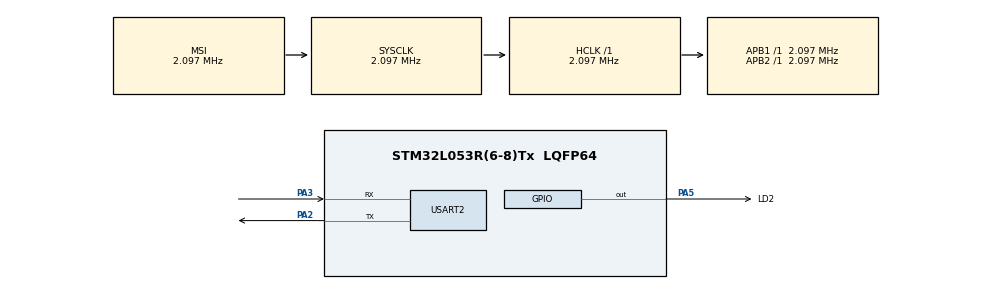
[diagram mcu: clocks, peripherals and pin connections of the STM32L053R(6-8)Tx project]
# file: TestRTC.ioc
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Mcu.Family=STM32L0
Mcu.Name=STM32L053R(6-8)Tx
Mcu.Package=LQFP64
NVIC.USART2_IRQn=true\:0\:0\:false\:false\:true\:true\:true
PA2.Mode=Asynchronous
PA2.Signal=USART2_TX
PA3.Mode=Asynchronous
PA3.Signal=USART2_RX
PA5.GPIO_Label=LD2
PA5.Signal=GPIO_Output
ProjectManager.HeapSize=0x200
ProjectManager.StackSize=0x400
ProjectManager.TargetToolchain=STM32CubeIDE
RCC.AHBFreq_Value=2097000
RCC.APB1Freq_Value=2097000
RCC.APB1TimFreq_Value=2097000
RCC.APB2Freq_Value=2097000
RCC.APB2TimFreq_Value=2097000
RCC.HSE_VALUE=8000000
RCC.HSI16_VALUE=16000000
RCC.HSI48_VALUE=48000000
RCC.HSI_VALUE=16000000
RCC.LSE_VALUE=32768
RCC.MSI_VALUE=2097000
RCC.SYSCLKFreq_VALUE=2097000
RCC.VCOOutputFreq_Value=48000000
RTC.Alarm-Alarm\ A=RTC_ALARM_A
RTC.Alarm_B-Alarm\ B=RTC_ALARM_B
RTC.Format=RTC_FORMAT_BIN
USART2.VirtualMode-Asynchronous=VM_ASYNC
VP_RTC_VS_RTC_Activate.Mode=RTC_Enabled
VP_RTC_VS_RTC_Alarm_A_Intern.Mode=Alarm A
VP_RTC_VS_RTC_Alarm_B_Intern.Mode=Alarm B
VP_RTC_VS_RTC_Calendar.Mode=RTC_Calendar
VP_RTC_VS_RTC_WakeUp_intern.Mode=WakeUp
board=custom

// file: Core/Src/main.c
/* USER CODE BEGIN Header */
/**
  ******************************************************************************
  * @file           : main.c
  * @brief          : Main program body
  ******************************************************************************
  * @attention
  *
  * <h2><center>&copy; Copyright (c) 2020 STMicroelectronics.
  * All rights reserved.</center></h2>
  *
  * This software component is licensed by ST under BSD 3-Clause license,
  * the "License"; You may not use this file except in compliance with the
  * License. You may obtain a copy of the License at:
  *                        opensource.org/licenses/BSD-3-Clause
  *
  ******************************************************************************
  */
/* USER CODE END Header */

#include "main.h"

/* USER CODE BEGIN Includes */
#include "gestionertc.h"
/* USER CODE END Includes */

RTC_HandleTypeDef hrtc;

UART_HandleTypeDef huart2;

/* USER CODE BEGIN PV */

uint32_t yesterday = 0;
uint32_t now = 0;
uint32_t errors = 0;

/* USER CODE END PV */

void SystemClock_Config(void);
static void MX_GPIO_Init(void);
static void MX_RTC_Init(void);
static void MX_USART2_UART_Init(void);
/* USER CODE BEGIN PFP */
static uint8_t doTest(uint32_t pattern, uint32_t seconds);
/* USER CODE END PFP */

int main(void)
{

  /* MCU Configuration--------------------------------------------------------*/

  /* Reset of all peripherals, Initializes the Flash interface and the Systick. */
  HAL_Init();

  /* Configure the system clock */
  SystemClock_Config();

  /* Initialize all configured peripherals */
  MX_GPIO_Init();
  MX_RTC_Init();
  MX_USART2_UART_Init();
  /* USER CODE BEGIN 2 */

  //SetOra(1580176798);

  uint32_t testPattern[24]={
		  1580176798,
		  1580515190,
		  1582934390,
		  1585699190,
		  1588291190,
		  1590969590,
		  1596239990,
		  1598918390,
		  1601510390,
		  1604188790,
		  1606780790,
		  1609459190,
		  1612094390,
		  1614513590,
		  1617191990,
		  1619783990,
		  1622462390,
		  1625054390,
		  1627732790,
		  1630411190,
		  1633003190,
		  1635681590,
		  1638273590,
		  1640951990
		  };

	//char buffer[100];
	//memset(buffer,0,100);

	//sprintf(buffer,"---- Starting tests (errors = %u) ----\n",errors);
	//HAL_UART_Transmit(&huart2, buffer, strnlen(buffer,100), HAL_MAX_DELAY);

	int patternIndex = 0;

  /* USER CODE END 2 */

  /* Infinite loop */
  while (1)
  {

    /* USER CODE BEGIN 3 */

	  if (!doTest(testPattern[patternIndex],10)){

		  errors++;

	  }

	  if (patternIndex==23){
		  patternIndex=0;
		  yesterday = 0;
		  now = 0;
		  char buffer[100];
		  memset(buffer,0,100);

		  //sprintf(buffer,"---- Starting tests (errors = %u) ----\n",errors);
		  //HAL_UART_Transmit(&huart2, buffer, strnlen(buffer,100), HAL_MAX_DELAY);
	  }
	  else
	  {
		  patternIndex++;
	  }

  }
  /* USER CODE END 3 */
}

void SystemClock_Config(void)
{
  RCC_OscInitTypeDef RCC_OscInitStruct = {0};
  RCC_ClkInitTypeDef RCC_ClkInitStruct = {0};
  RCC_PeriphCLKInitTypeDef PeriphClkInit = {0};

  /** Configure the main internal regulator output voltage
  */
  __HAL_PWR_VOLTAGESCALING_CONFIG(PWR_REGULATOR_VOLTAGE_SCALE1);
  /** Initializes the CPU, AHB and APB busses clocks
  */
  RCC_OscInitStruct.OscillatorType = RCC_OSCILLATORTYPE_LSI|RCC_OSCILLATORTYPE_MSI;
  RCC_OscInitStruct.LSIState = RCC_LSI_ON;
  RCC_OscInitStruct.MSIState = RCC_MSI_ON;
  RCC_OscInitStruct.MSICalibrationValue = 0;
  RCC_OscInitStruct.MSIClockRange = RCC_MSIRANGE_5;
  RCC_OscInitStruct.PLL.PLLState = RCC_PLL_NONE;
  if (HAL_RCC_OscConfig(&RCC_OscInitStruct) != HAL_OK)
  {
    Error_Handler();
  }
  /** Initializes the CPU, AHB and APB busses clocks
  */
  RCC_ClkInitStruct.ClockType = RCC_CLOCKTYPE_HCLK|RCC_CLOCKTYPE_SYSCLK
                              |RCC_CLOCKTYPE_PCLK1|RCC_CLOCKTYPE_PCLK2;
  RCC_ClkInitStruct.SYSCLKSource = RCC_SYSCLKSOURCE_MSI;
  RCC_ClkInitStruct.AHBCLKDivider = RCC_SYSCLK_DIV1;
  RCC_ClkInitStruct.APB1CLKDivider = RCC_HCLK_DIV1;
  RCC_ClkInitStruct.APB2CLKDivider = RCC_HCLK_DIV1;

  if (HAL_RCC_ClockConfig(&RCC_ClkInitStruct, FLASH_LATENCY_0) != HAL_OK)
  {
    Error_Handler();
  }
  PeriphClkInit.PeriphClockSelection = RCC_PERIPHCLK_USART2|RCC_PERIPHCLK_RTC;
  PeriphClkInit.Usart2ClockSelection = RCC_USART2CLKSOURCE_PCLK1;
  PeriphClkInit.RTCClockSelection = RCC_RTCCLKSOURCE_LSI;
  if (HAL_RCCEx_PeriphCLKConfig(&PeriphClkInit) != HAL_OK)
  {
    Error_Handler();
  }
}

static void MX_RTC_Init(void)
{

  RTC_TimeTypeDef sTime = {0};
  RTC_DateTypeDef sDate = {0};
  RTC_AlarmTypeDef sAlarm = {0};

  /** Initialize RTC Only
  */
  hrtc.Instance = RTC;
  hrtc.Init.HourFormat = RTC_HOURFORMAT_24;
  hrtc.Init.AsynchPrediv = 127;
  hrtc.Init.SynchPrediv = 255;
  hrtc.Init.OutPut = RTC_OUTPUT_DISABLE;
  hrtc.Init.OutPutRemap = RTC_OUTPUT_REMAP_NONE;
  hrtc.Init.OutPutPolarity = RTC_OUTPUT_POLARITY_HIGH;
  hrtc.Init.OutPutType = RTC_OUTPUT_TYPE_OPENDRAIN;
  if (HAL_RTC_Init(&hrtc) != HAL_OK)
  {
    Error_Handler();
  }

  /** Initialize RTC and set the Time and Date
  */
  sTime.Hours = 0;
  sTime.Minutes = 0;
  sTime.Seconds = 0;
  sTime.DayLightSaving = RTC_DAYLIGHTSAVING_NONE;
  sTime.StoreOperation = RTC_STOREOPERATION_RESET;
  if (HAL_RTC_SetTime(&hrtc, &sTime, RTC_FORMAT_BIN) != HAL_OK)
  {
    Error_Handler();
  }
  sDate.WeekDay = RTC_WEEKDAY_MONDAY;
  sDate.Month = RTC_MONTH_JANUARY;
  sDate.Date = 1;
  sDate.Year = 0;

  if (HAL_RTC_SetDate(&hrtc, &sDate, RTC_FORMAT_BIN) != HAL_OK)
  {
    Error_Handler();
  }
  /** Enable the Alarm A
  */
  sAlarm.AlarmTime.Hours = 0;
  sAlarm.AlarmTime.Minutes = 0;
  sAlarm.AlarmTime.Seconds = 0;
  sAlarm.AlarmTime.SubSeconds = 0;
  sAlarm.AlarmTime.DayLightSaving = RTC_DAYLIGHTSAVING_NONE;
  sAlarm.AlarmTime.StoreOperation = RTC_STOREOPERATION_RESET;
  sAlarm.AlarmMask = RTC_ALARMMASK_NONE;
  sAlarm.AlarmSubSecondMask = RTC_ALARMSUBSECONDMASK_ALL;
  sAlarm.AlarmDateWeekDaySel = RTC_ALARMDATEWEEKDAYSEL_DATE;
  sAlarm.AlarmDateWeekDay = 1;
  sAlarm.Alarm = RTC_ALARM_A;
  if (HAL_RTC_SetAlarm(&hrtc, &sAlarm, RTC_FORMAT_BIN) != HAL_OK)
  {
    Error_Handler();
  }
  /** Enable the Alarm B
  */
  sAlarm.AlarmDateWeekDay = 1;
  sAlarm.Alarm = RTC_ALARM_B;
  if (HAL_RTC_SetAlarm(&hrtc, &sAlarm, RTC_FORMAT_BIN) != HAL_OK)
  {
    Error_Handler();
  }
  /** Enable the WakeUp
  */
  if (HAL_RTCEx_SetWakeUpTimer(&hrtc, 0, RTC_WAKEUPCLOCK_RTCCLK_DIV16) != HAL_OK)
  {
    Error_Handler();
  }

}

static void MX_USART2_UART_Init(void)
{

  huart2.Instance = USART2;
  huart2.Init.BaudRate = 115200;
  huart2.Init.WordLength = UART_WORDLENGTH_8B;
  huart2.Init.StopBits = UART_STOPBITS_1;
  huart2.Init.Parity = UART_PARITY_NONE;
  huart2.Init.Mode = UART_MODE_TX_RX;
  huart2.Init.HwFlowCtl = UART_HWCONTROL_NONE;
  huart2.Init.OverSampling = UART_OVERSAMPLING_16;
  huart2.Init.OneBitSampling = UART_ONE_BIT_SAMPLE_DISABLE;
  huart2.AdvancedInit.AdvFeatureInit = UART_ADVFEATURE_NO_INIT;
  if (HAL_UART_Init(&huart2) != HAL_OK)
  {
    Error_Handler();
  }

}

static void MX_GPIO_Init(void)
{
  GPIO_InitTypeDef GPIO_InitStruct = {0};

  /* GPIO Ports Clock Enable */
  __HAL_RCC_GPIOA_CLK_ENABLE();

  /*Configure GPIO pin Output Level */
  HAL_GPIO_WritePin(LD2_GPIO_Port, LD2_Pin, GPIO_PIN_RESET);

  /*Configure GPIO pin : LD2_Pin */
  GPIO_InitStruct.Pin = LD2_Pin;
  GPIO_InitStruct.Mode = GPIO_MODE_OUTPUT_PP;
  GPIO_InitStruct.Pull = GPIO_NOPULL;
  GPIO_InitStruct.Speed = GPIO_SPEED_FREQ_LOW;
  HAL_GPIO_Init(LD2_GPIO_Port, &GPIO_InitStruct);

}

/* USER CODE BEGIN 4 */

static uint8_t doTest(uint32_t pattern, uint32_t seconds){

	SetOraNew((time_t)pattern);

	HAL_Delay(1000);

	uint32_t delay = 0;

	char buffer[100];
	memset(buffer,0,100);

	sprintf(buffer,"Timestamp %u 1\n",pattern);
	HAL_UART_Transmit(&huart2, buffer, strnlen(buffer,100), HAL_MAX_DELAY);

	do{

		memset(buffer,0,100);
		//yesterday = now;

		HAL_GPIO_TogglePin(LD2_GPIO_Port, LD2_Pin);

		/*
		if ((now-yesterday<0 || now-yesterday>2) && yesterday>0){

		  sprintf(buffer,"Error! Wrong Timestamp. Now is %u and Yesterday is %u\n",now,yesterday);
		  HAL_UART_Transmit(&huart2, buffer, strnlen(buffer,100), HAL_MAX_DELAY);
		  HAL_GPIO_WritePin(LD2_GPIO_Port, LD2_Pin,SET);
		  return 0;

		}*/

		now = (uint32_t)GetOraNew();
		sprintf(buffer,"Timestamp %u 0\n",now);
		HAL_UART_Transmit(&huart2, buffer, strnlen(buffer,100), HAL_MAX_DELAY);

		HAL_Delay(1000);

		delay++;

	}
	while(delay<seconds);

	return 1;

}

/* USER CODE END 4 */

void Error_Handler(void)
{
  /* USER CODE BEGIN Error_Handler_Debug */
  /* User can add his own implementation to report the HAL error return state */
	char buffer[100];
	memset(buffer,0,100);
	sprintf(buffer,"Fatal Error\n");
	HAL_UART_Transmit(&huart2, buffer, strnlen(buffer,100), HAL_MAX_DELAY);
	while(1){

	}
  /* USER CODE END Error_Handler_Debug */
}

/************************ (C) COPYRIGHT STMicroelectronics *****END OF FILE****/
